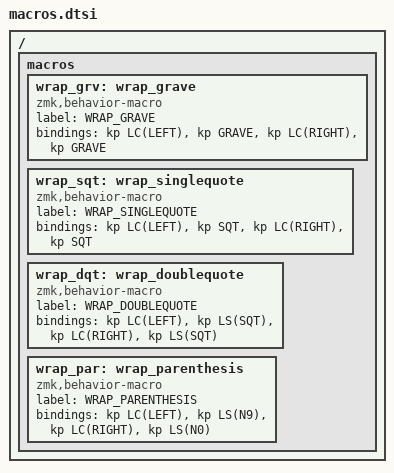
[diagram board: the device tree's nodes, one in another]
/ {
    macros {
        wrap_grv: wrap_grave {
            label = "WRAP_GRAVE";
            compatible = "zmk,behavior-macro";
            #binding-cells = <0>;
            bindings
                = <&kp LC(LEFT) &kp GRAVE>
				, <&kp LC(RIGHT) &kp GRAVE>
                ;
        };

        wrap_sqt: wrap_singlequote {
            label = "WRAP_SINGLEQUOTE";
            compatible = "zmk,behavior-macro";
            #binding-cells = <0>;
            bindings
                = <&kp LC(LEFT) &kp SQT>
				, <&kp LC(RIGHT) &kp SQT>
                ;
        };

        wrap_dqt: wrap_doublequote {
            label = "WRAP_DOUBLEQUOTE";
            compatible = "zmk,behavior-macro";
            #binding-cells = <0>;
            bindings
                = <&kp LC(LEFT) &kp LS(SQT)>
				, <&kp LC(RIGHT) &kp LS(SQT)>
                ;
        };

        wrap_par: wrap_parenthesis {
            label = "WRAP_PARENTHESIS";
            compatible = "zmk,behavior-macro";
            #binding-cells = <0>;
            bindings
                = <&kp LC(LEFT) &kp LS(N9)>
				, <&kp LC(RIGHT) &kp LS(N0)>
                ;
        };
    };
};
